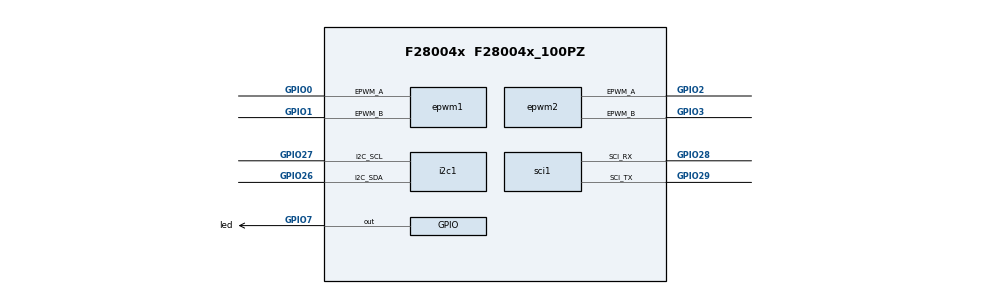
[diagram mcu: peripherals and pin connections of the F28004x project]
/**
 *
 * @cliArgs --device "F28004x" --part "F28004x_100PZ" --package "F28004x_100PZ" --context "system" --product "C2000WARE@26.01.00.00"
 * @versions {"tool":"1.28.1+4785"}
 */
scripting.excludeFromBuild("board.cmd.genlibs");
scripting.excludeFromBuild("board.opt");
scripting.excludeFromBuild("board.json");
scripting.excludeFromBuild("pinmux.csv");
scripting.excludeFromBuild("c2000ware_libraries.cmd.genlibs");
scripting.excludeFromBuild("c2000ware_libraries.opt");
scripting.excludeFromBuild("c2000ware_libraries.c");
scripting.excludeFromBuild("c2000ware_libraries.h");

/**
 * Import the modules used in this configuration.
 */
const adc            = scripting.addModule("/driverlib/adc.js", {}, false);
const adc1           = adc.addInstance();
const asysctl        = scripting.addModule("/driverlib/asysctl.js");
const cla            = scripting.addModule("/driverlib/cla.js", {}, false);
const cla1           = cla.addInstance();
const device_support = scripting.addModule("/driverlib/device_support.js");
const dma            = scripting.addModule("/driverlib/dma.js", {}, false);
const dma1           = dma.addInstance();
const epwm           = scripting.addModule("/driverlib/epwm.js", {}, false);
const epwm1          = epwm.addInstance();
const epwm2          = epwm.addInstance();
const gpio           = scripting.addModule("/driverlib/gpio.js", {}, false);
const gpio1          = gpio.addInstance();
const i2c            = scripting.addModule("/driverlib/i2c.js", {}, false);
const i2c1           = i2c.addInstance();
const memcfg         = scripting.addModule("/driverlib/memcfg.js");
const sci            = scripting.addModule("/driverlib/sci.js", {}, false);
const sci1           = sci.addInstance();
const sysctl         = scripting.addModule("/driverlib/sysctl.js");
const FPUfastRTS     = scripting.addModule("/libraries/math/FPUfastRTS/FPUfastRTS.js", {}, false);
const FPUfastRTS1    = FPUfastRTS.addInstance();

/**
 * Write custom configuration values to the imported modules.
 */
adc1.$name              = "myADC0";
adc1.adcClockPrescaler  = "ADC_CLK_DIV_4_0";
adc1.interruptPulseMode = "ADC_PULSE_END_OF_CONV";
adc1.enabledSOCs        = ["ADC_SOC_NUMBER0"];
adc1.soc0Trigger        = "ADC_TRIGGER_EPWM1_SOCA";
adc1.soc0Channel        = "ADC_CH_ADCIN5";
adc1.soc0SampleWindow   = 10;
adc1.enabledInts        = ["ADC_INT_NUMBER1"];
adc1.enableInterrupt1   = true;

asysctl.analogReferenceVoltage = "1P65";

cla1.$name              = "myCLA0";
cla1.trigger_CLA_TASK_1 = "CLA_TRIGGER_ADCA1";
cla1.cpuint_CLA_TASK_1  = false;
cla1.cpuint_CLA_TASK_2  = false;
cla1.cpuint_CLA_TASK_3  = false;
cla1.cpuint_CLA_TASK_4  = false;
cla1.cpuint_CLA_TASK_5  = false;
cla1.cpuint_CLA_TASK_6  = false;
cla1.cpuint_CLA_TASK_7  = false;
cla1.cpuint_CLA_TASK_8  = false;

const divider1       = system.clockTree["CLBCLKDIV"];
divider1.divideValue = 2;

const divider2       = system.clockTree["LOSPCP"];
divider2.divideValue = 1;

const divider3       = system.clockTree["PLL_ODIV"];
divider3.divideValue = 2;

const divider4       = system.clockTree["SYSCLKDIVSEL"];
divider4.divideValue = 1;

const multiplier2         = system.clockTree["PLL_IMULT"];
multiplier2.multiplyValue = 10;

const mux2       = system.clockTree["OSCCLKSRCSEL"];
mux2.inputSelect = "X1_XTAL";

dma1.$name                = "myDMA0";
dma1.enableTriggers       = true;
dma1.triggerSource        = "DMA_TRIGGER_ADCA1";
dma1.emulationMode        = "DMA_EMULATION_FREE_RUN";
dma1.continuousModeConfig = "DMA_CFG_CONTINUOUS_ENABLE";
dma1.transferSize         = 400;
dma1.srcAddressManual     = 0xB00;
dma1.destTransferStep     = 1;
dma1.destWrapSize         = 400;
dma1.destWrapStep         = -400;

epwm1.epwmTimebase_hsClockDiv                                    = "EPWM_HSCLOCK_DIVIDER_1";
epwm1.epwmTimebase_period                                        = 2500;
epwm1.epwmTimebase_counterMode                                   = "EPWM_COUNTER_MODE_UP_DOWN";
epwm1.epwmActionQualifier_EPWM_AQ_OUTPUT_A_ON_TIMEBASE_ZERO      = "EPWM_AQ_OUTPUT_HIGH";
epwm1.epwmActionQualifier_EPWM_AQ_OUTPUT_A_ON_TIMEBASE_PERIOD    = "EPWM_AQ_OUTPUT_LOW";
epwm1.epwmActionQualifier_EPWM_AQ_OUTPUT_A_ON_TIMEBASE_UP_CMPA   = "EPWM_AQ_OUTPUT_LOW";
epwm1.epwmActionQualifier_EPWM_AQ_OUTPUT_A_ON_TIMEBASE_DOWN_CMPA = "EPWM_AQ_OUTPUT_HIGH";
epwm1.epwmDeadband_polarityFED                                   = "EPWM_DB_POLARITY_ACTIVE_LOW";
epwm1.epwmDeadband_enableRED                                     = true;
epwm1.epwmDeadband_enableFED                                     = true;
epwm1.epwmDeadband_delayRED                                      = 10;
epwm1.epwmDeadband_delayFED                                      = 10;
epwm1.$name                                                      = "myEPWM1";
epwm1.epwmEventTrigger_enableInterrupt                           = true;
epwm1.epwmEventTrigger_interruptSource                           = "EPWM_INT_TBCTR_PERIOD";
epwm1.epwmEventTrigger_interruptEventCount                       = "2";
epwm1.epwmEventTrigger_EPWM_SOC_A_triggerEnable                  = true;
epwm1.epwmEventTrigger_EPWM_SOC_A_triggerSource                  = "EPWM_SOC_TBCTR_ZERO";
epwm1.epwmEventTrigger_EPWM_SOC_A_triggerEventPrescalar          = "1";
epwm1.epwmActionQualifier_EPWM_AQ_OUTPUT_B_ON_TIMEBASE_ZERO      = "EPWM_AQ_OUTPUT_LOW";
epwm1.epwmActionQualifier_EPWM_AQ_OUTPUT_B_ON_TIMEBASE_PERIOD    = "EPWM_AQ_OUTPUT_HIGH";
epwm1.epwmActionQualifier_EPWM_AQ_OUTPUT_B_ON_TIMEBASE_UP_CMPA   = "EPWM_AQ_OUTPUT_HIGH";
epwm1.epwmActionQualifier_EPWM_AQ_OUTPUT_B_ON_TIMEBASE_DOWN_CMPA = "EPWM_AQ_OUTPUT_LOW";
epwm1.epwmTimebase_syncOutPulseMode                              = "EPWM_SYNC_OUT_PULSE_ON_COUNTER_ZERO";
epwm1.epwm.$assign                                               = "EPWM1";
epwm1.epwm.epwm_aPin.$assign                                     = "GPIO0";
epwm1.epwm.epwm_bPin.$assign                                     = "GPIO1";

epwm2.epwmTimebase_hsClockDiv                                    = "EPWM_HSCLOCK_DIVIDER_1";
epwm2.epwmTimebase_period                                        = 2500;
epwm2.epwmTimebase_counterMode                                   = "EPWM_COUNTER_MODE_UP_DOWN";
epwm2.$name                                                      = "myEPWM2";
epwm2.epwmActionQualifier_EPWM_AQ_OUTPUT_A_ON_TIMEBASE_ZERO      = "EPWM_AQ_OUTPUT_HIGH";
epwm2.epwmActionQualifier_EPWM_AQ_OUTPUT_A_ON_TIMEBASE_PERIOD    = "EPWM_AQ_OUTPUT_LOW";
epwm2.epwmActionQualifier_EPWM_AQ_OUTPUT_A_ON_TIMEBASE_UP_CMPA   = "EPWM_AQ_OUTPUT_LOW";
epwm2.epwmActionQualifier_EPWM_AQ_OUTPUT_A_ON_TIMEBASE_DOWN_CMPA = "EPWM_AQ_OUTPUT_HIGH";
epwm2.epwmDeadband_enableRED                                     = true;
epwm2.epwmDeadband_enableFED                                     = true;
epwm2.epwmTimebase_phaseEnable                                   = true;
epwm2.epwmTimebase_counterModeAfterSync                          = "EPWM_COUNT_MODE_UP_AFTER_SYNC";
epwm2.epwmActionQualifier_EPWM_AQ_OUTPUT_B_ON_TIMEBASE_ZERO      = "EPWM_AQ_OUTPUT_LOW";
epwm2.epwmActionQualifier_EPWM_AQ_OUTPUT_B_ON_TIMEBASE_PERIOD    = "EPWM_AQ_OUTPUT_HIGH";
epwm2.epwmActionQualifier_EPWM_AQ_OUTPUT_B_ON_TIMEBASE_UP_CMPA   = "EPWM_AQ_OUTPUT_HIGH";
epwm2.epwmActionQualifier_EPWM_AQ_OUTPUT_B_ON_TIMEBASE_DOWN_CMPA = "EPWM_AQ_OUTPUT_LOW";
epwm2.epwmDeadband_polarityFED                                   = "EPWM_DB_POLARITY_ACTIVE_LOW";
epwm2.epwmDeadband_delayRED                                      = 10;
epwm2.epwmDeadband_delayFED                                      = 10;
epwm2.epwm.$assign                                               = "EPWM2";
epwm2.epwm.epwm_aPin.$assign                                     = "GPIO2";
epwm2.epwm.epwm_bPin.$assign                                     = "GPIO3";

gpio1.$name             = "led";
gpio1.direction         = "GPIO_DIR_MODE_OUT";
gpio1.writeInitialValue = true;
gpio1.initialValue      = 1;
gpio1.gpioPin.$assign   = "GPIO7";

i2c1.$name                  = "oled";
i2c1.duty                   = "I2C_DUTYCYCLE_50";
i2c1.bitCount               = "I2C_BITCOUNT_8";
i2c1.targetAddress          = 0x3C;
i2c1.registerInterrupts     = true;
i2c1.useInterrupts          = false;
i2c1.i2c.$assign            = "I2CA";
i2c1.i2c.i2c_sdaPin.$assign = "GPIO26";
i2c1.i2c.i2c_sclPin.$assign = "GPIO27";

memcfg.config_MEMCFG_SECT_LS0        = "CLA_prog";
memcfg.config_MEMCFG_SECT_LS1        = "CLA_prog";
memcfg.config_MEMCFG_SECT_LS2        = "CLA_prog";
memcfg.config_MEMCFG_SECT_LS3        = "CLA_prog";
memcfg.config_MEMCFG_SECT_LS4        = "CLA_data";
memcfg.config_MEMCFG_SECT_LS5        = "CLA_data";
memcfg.config_MEMCFG_SECT_LS6        = "CLA_data";
memcfg.config_MEMCFG_SECT_LS7        = "CLA_data";
memcfg.init_MEMCFG_SECT_MSGCPUTOCLA1 = true;
memcfg.init_MEMCFG_SECT_MSGCLA1TOCPU = true;

sci1.$name                 = "VOFA_UART";
sci1.useInterrupts         = false;
sci1.baudRates             = 460800;
sci1.sci.$assign           = "SCIA";
sci1.sci.sci_rxPin.$assign = "GPIO28";
sci1.sci.sci_txPin.$assign = "GPIO29";
sci1.rxQual.$name          = "myGPIOQUAL0";
sci1.txQual.$name          = "myGPIOQUAL1";

sysctl.enable_SYSCTL_PERIPH_CLK_HRPWM  = false;
sysctl.enable_SYSCTL_PERIPH_CLK_PMBUSA = false;
sysctl.enable_SYSCTL_PERIPH_CLK_LINA   = false;
sysctl.enable_SYSCTL_PERIPH_CLK_FSIRXA = false;
sysctl.enable_SYSCTL_PERIPH_CLK_FSITXA = false;
sysctl.enable_SYSCTL_PERIPH_CLK_PGA1   = false;
sysctl.enable_SYSCTL_PERIPH_CLK_PGA2   = false;
sysctl.enable_SYSCTL_PERIPH_CLK_PGA3   = false;
sysctl.enable_SYSCTL_PERIPH_CLK_PGA4   = false;
sysctl.enable_SYSCTL_PERIPH_CLK_PGA5   = false;
sysctl.enable_SYSCTL_PERIPH_CLK_PGA7   = false;
sysctl.enable_SYSCTL_PERIPH_CLK_PGA6   = false;
sysctl.enable_SYSCTL_PERIPH_CLK_CANA   = false;
sysctl.enable_SYSCTL_PERIPH_CLK_CANB   = false;
sysctl.enable_SYSCTL_PERIPH_CLK_EQEP1  = false;
sysctl.enable_SYSCTL_PERIPH_CLK_EQEP2  = false;

FPUfastRTS1.$name = "myFFR0";
